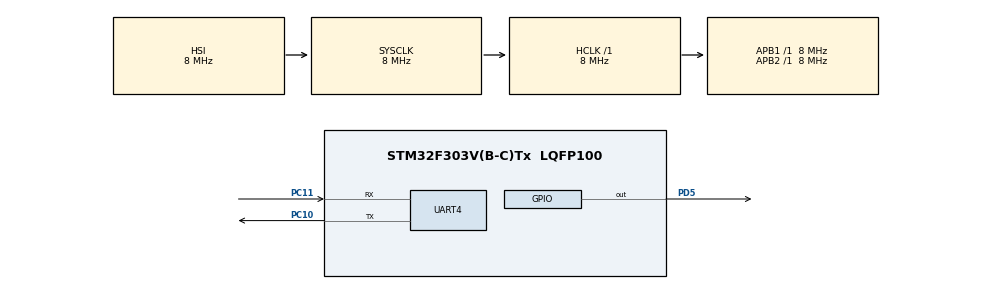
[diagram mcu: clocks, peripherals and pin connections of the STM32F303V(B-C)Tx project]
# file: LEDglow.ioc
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Mcu.Family=STM32F3
Mcu.Name=STM32F303V(B-C)Tx
Mcu.Package=LQFP100
NVIC.PriorityGroup=NVIC_PRIORITYGROUP_4
PA13.Mode=Serial_Wire
PA13.Signal=SYS_JTMS-SWDIO
PA14.Mode=Serial_Wire
PA14.Signal=SYS_JTCK-SWCLK
PC10.Mode=Asynchronous
PC10.Signal=UART4_TX
PC11.Mode=Asynchronous
PC11.Signal=UART4_RX
PC14-OSC32_IN.Mode=LSE-External-Oscillator
PC14-OSC32_IN.Signal=RCC_OSC32_IN
PC15-OSC32_OUT.Mode=LSE-External-Oscillator
PC15-OSC32_OUT.Signal=RCC_OSC32_OUT
PD5.PinState=GPIO_PIN_SET
PD5.Signal=GPIO_Output
ProjectManager.HeapSize=0x200
ProjectManager.StackSize=0x400
ProjectManager.TargetToolchain=MDK-ARM V5
RCC.AHBFreq_Value=8000000
RCC.APB1Freq_Value=8000000
RCC.APB2Freq_Value=8000000
RCC.CortexFreq_Value=8000000
RCC.HSE_VALUE=8000000
RCC.HSI_VALUE=8000000
RCC.SYSCLKFreq_VALUE=8000000
board=custom

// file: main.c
/* USER CODE BEGIN Header */
/**
  ******************************************************************************
  * @file           : main.c
  * @brief          : Main program body
  ******************************************************************************
  * @attention
  *
  * <h2><center>&copy; Copyright (c) 2019 STMicroelectronics.
  * All rights reserved.</center></h2>
  *
  * This software component is licensed by ST under BSD 3-Clause license,
  * the "License"; You may not use this file except in compliance with the
  * License. You may obtain a copy of the License at:
  *                        opensource.org/licenses/BSD-3-Clause
  *
  ******************************************************************************
  */
/* USER CODE END Header */

#include "main.h"

UART_HandleTypeDef huart4;

void SystemClock_Config(void);
static void MX_GPIO_Init(void);
static void MX_UART4_Init(void);

int main(void)
{

  /* MCU Configuration--------------------------------------------------------*/

  /* Reset of all peripherals, Initializes the Flash interface and the Systick. */
  HAL_Init();

  /* Configure the system clock */
  SystemClock_Config();

  /* Initialize all configured peripherals */
  MX_GPIO_Init();
  MX_UART4_Init();
  /* USER CODE BEGIN 2 */
	uint8_t r[0]={'x'};

  /* USER CODE END 2 */

  /* Infinite loop */
  /* USER CODE BEGIN WHILE */
  while (1)
  {
		HAL_UART_Transmit(&huart4,r,sizeof(r),100);
		if(r[0]=="A")
		{
			HAL_GPIO_WritePin(GPIOD,GPIO_PIN_5,1);
		}
		else if(r[0]=='B')
		{
			HAL_GPIO_WritePin(GPIOD,GPIO_PIN_5,0);
		}
		HAL_UART_Receive(&huart4,r,sizeof(r),100);
    /* USER CODE END WHILE */

  }
}

void SystemClock_Config(void)
{
  RCC_OscInitTypeDef RCC_OscInitStruct = {0};
  RCC_ClkInitTypeDef RCC_ClkInitStruct = {0};
  RCC_PeriphCLKInitTypeDef PeriphClkInit = {0};

  /** Initializes the CPU, AHB and APB busses clocks
  */
  RCC_OscInitStruct.OscillatorType = RCC_OSCILLATORTYPE_HSI;
  RCC_OscInitStruct.HSIState = RCC_HSI_ON;
  RCC_OscInitStruct.HSICalibrationValue = RCC_HSICALIBRATION_DEFAULT;
  RCC_OscInitStruct.PLL.PLLState = RCC_PLL_NONE;
  if (HAL_RCC_OscConfig(&RCC_OscInitStruct) != HAL_OK)
  {
    Error_Handler();
  }
  /** Initializes the CPU, AHB and APB busses clocks
  */
  RCC_ClkInitStruct.ClockType = RCC_CLOCKTYPE_HCLK|RCC_CLOCKTYPE_SYSCLK
                              |RCC_CLOCKTYPE_PCLK1|RCC_CLOCKTYPE_PCLK2;
  RCC_ClkInitStruct.SYSCLKSource = RCC_SYSCLKSOURCE_HSI;
  RCC_ClkInitStruct.AHBCLKDivider = RCC_SYSCLK_DIV1;
  RCC_ClkInitStruct.APB1CLKDivider = RCC_HCLK_DIV1;
  RCC_ClkInitStruct.APB2CLKDivider = RCC_HCLK_DIV1;

  if (HAL_RCC_ClockConfig(&RCC_ClkInitStruct, FLASH_LATENCY_0) != HAL_OK)
  {
    Error_Handler();
  }
  PeriphClkInit.PeriphClockSelection = RCC_PERIPHCLK_UART4;
  PeriphClkInit.Uart4ClockSelection = RCC_UART4CLKSOURCE_PCLK1;
  if (HAL_RCCEx_PeriphCLKConfig(&PeriphClkInit) != HAL_OK)
  {
    Error_Handler();
  }
}

static void MX_UART4_Init(void)
{

  huart4.Instance = UART4;
  huart4.Init.BaudRate = 115200;
  huart4.Init.WordLength = UART_WORDLENGTH_8B;
  huart4.Init.StopBits = UART_STOPBITS_1;
  huart4.Init.Parity = UART_PARITY_NONE;
  huart4.Init.Mode = UART_MODE_TX_RX;
  huart4.Init.HwFlowCtl = UART_HWCONTROL_NONE;
  huart4.Init.OverSampling = UART_OVERSAMPLING_16;
  huart4.Init.OneBitSampling = UART_ONE_BIT_SAMPLE_DISABLE;
  huart4.AdvancedInit.AdvFeatureInit = UART_ADVFEATURE_NO_INIT;
  if (HAL_UART_Init(&huart4) != HAL_OK)
  {
    Error_Handler();
  }

}

static void MX_GPIO_Init(void)
{
  GPIO_InitTypeDef GPIO_InitStruct = {0};

  /* GPIO Ports Clock Enable */
  __HAL_RCC_GPIOC_CLK_ENABLE();
  __HAL_RCC_GPIOA_CLK_ENABLE();
  __HAL_RCC_GPIOD_CLK_ENABLE();

  /*Configure GPIO pin Output Level */
  HAL_GPIO_WritePin(GPIOD, GPIO_PIN_5, GPIO_PIN_SET);

  /*Configure GPIO pin : PD5 */
  GPIO_InitStruct.Pin = GPIO_PIN_5;
  GPIO_InitStruct.Mode = GPIO_MODE_OUTPUT_PP;
  GPIO_InitStruct.Pull = GPIO_NOPULL;
  GPIO_InitStruct.Speed = GPIO_SPEED_FREQ_LOW;
  HAL_GPIO_Init(GPIOD, &GPIO_InitStruct);

}

void Error_Handler(void)
{
}

/************************ (C) COPYRIGHT STMicroelectronics *****END OF FILE****/
